AUTOSAR XML (schema 4-2-2)
standard types defined: boolean, uint8
package /Communication/DataTransformation
  data transformation set New_Transformer_Configuration
    transformation technology Fingerprint_SOME_IP_Transformer: someip-transformation-description=byte-order=big-endian
package /Communication/PDUs
  pdu Delete_RequestSignalIPDU: contained-i-pdu-props={collection-semantics=LAST-IS-BEST, header-id-short-header=1}
    signal Delete_Request: 4 bit, compu-method=DeleteFunction_FingerPrintDelete1, someip-transformation-i-signal-props=Fingerprint_SOME_IP_Transformer, to TC297
  pdu Delete_ResultSignalIPDU: contained-i-pdu-props={collection-semantics=LAST-IS-BEST, header-id-short-header=2}
    signal Delete_Result: 1 bit, compu {0=Delete_Result_Sucessful, 1=Delete_Result_Failed}, someip-transformation-i-signal-props=Fingerprint_SOME_IP_Transformer, to J6
  pdu DoorStatusSignalIPDU: contained-i-pdu-props={collection-semantics=LAST-IS-BEST, header-id-short-header=3}
    signal DoorStatus: 1 bit, big-endian, compu {0=DoorStatusClosed, 1=DoorStatusOpen}, someip-transformation-i-signal-props=Fingerprint_SOME_IP_Transformer, to J6
  4 x i signal i pdu group:
    J6_BusSystem57_Rx: communication-direction=IN
      i-signal-i-pdus:
        Learn_PercentSignalIPDU
        Inactive_ResultSignalIPDU
        PowermodeSignalIPDU
        Delete_ResultSignalIPDU
        DoorStatusSignalIPDU
        Learn_ResultSignalIPDU
    J6_BusSystem57_Tx: communication-direction=OUT, i-signal-i-pdus=[Inactive_RequestSignalIPDU, Delete_RequestSignalIPDU, Learn_RequestSignalIPDU]
    TC297_BusSystem56_Rx: communication-direction=IN, i-signal-i-pdus=[Learn_RequestSignalIPDU, Delete_RequestSignalIPDU, Inactive_RequestSignalIPDU]
    TC297_BusSystem56_Tx: communication-direction=OUT
      i-signal-i-pdus:
        PowermodeSignalIPDU
        DoorStatusSignalIPDU
        Inactive_ResultSignalIPDU
        Delete_ResultSignalIPDU
        Learn_ResultSignalIPDU
        Learn_PercentSignalIPDU
  pdu Inactive_RequestSignalIPDU
    signal Inactive_Request: 1 bit, compu {0=Learn_Inactive}, someip-transformation-i-signal-props=Fingerprint_SOME_IP_Transformer, to TC297
  pdu Inactive_ResultSignalIPDU: contained-i-pdu-props={collection-semantics=LAST-IS-BEST, header-id-short-header=4}
    signal Inactive_Result: 1 bit, compu {0=Inactive_ResultSucessful, 1=Inactive_ResultFailed}, someip-transformation-i-signal-props=Fingerprint_SOME_IP_Transformer, to J6
  pdu Learn_PercentSignalIPDU: contained-i-pdu-props={collection-semantics=LAST-IS-BEST, header-id-short-header=6}
    signal Learn_Percent: 8 bit, someip-transformation-i-signal-props=Fingerprint_SOME_IP_Transformer, to J6
  pdu Learn_RequestSignalIPDU: contained-i-pdu-props={collection-semantics=LAST-IS-BEST, header-id-short-header=7}
    signal Learn_Request: 1 bit, compu {0=Learn_Active}, someip-transformation-i-signal-props=Fingerprint_SOME_IP_Transformer, to TC297
  pdu Learn_ResultSignalIPDU: contained-i-pdu-props={collection-semantics=LAST-IS-BEST, header-id-short-header=8}
    signal Learn_Result: 3 bit, compu-method=Learn_Result1, someip-transformation-i-signal-props=Fingerprint_SOME_IP_Transformer, to J6
  pdu PowermodeSignalIPDU: contained-i-pdu-props={collection-semantics=LAST-IS-BEST, header-id-short-header=9}
    signal Powermode: 2 bit, compu {1=SwitchRequest_ACC, 0=SwitchRequest_OFF, 2=SwitchRequest_RUN}, someip-transformation-i-signal-props=Fingerprint_SOME_IP_Transformer, to J6
package /DataTypeMappingSets
  data type mapping set Data_Type_Mappings
    data-type-maps:
      application-data-type=AdtDelete_Request1, implementation-data-type=IdtDelete_Request1
      application-data-type=AdtDelete_Status1, implementation-data-type=IdtDelete_Status1
      application-data-type=AdtDoorStatus1, implementation-data-type=IdtDoorStatus1
      application-data-type=AdtLearn_Inative1, implementation-data-type=IdtLearn_Inative1
      application-data-type=AdtLearn_Percent1, implementation-data-type=IdtLearn_Percent1
      application-data-type=AdtInactive_Result1, implementation-data-type=IdtInactive_Result1
      application-data-type=AdtLearn_Request1, implementation-data-type=IdtLearn_Request1
      application-data-type=AdtLearn_Result1, implementation-data-type=IdtLearn_Result1
      application-data-type=AdtPowerModeStatus1, implementation-data-type=IdtPowerModeStatus1
package /DataTypes/ApplicationDataTypes
  9 x app type:
    AdtDelete_Request1: category=VALUE, compu-method=DeleteFunction_FingerPrintDelete1
    AdtDelete_Status1: category=BOOLEAN, sw-calibration-access=READ-WRITE, compu {0=Delete_Result_Sucessful, 1=Delete_Result_Failed}, sw-interpolation-method=USEINPUTNEAREST
    AdtDoorStatus1: category=BOOLEAN, sw-calibration-access=READ-WRITE, compu {0=DoorStatusClosed, 1=DoorStatusOpen}, sw-refresh-timing={cse-code=3, cse-code-factor=200}
    AdtInactive_Result1: category=BOOLEAN, compu {0=Inactive_ResultSucessful, 1=Inactive_ResultFailed}
    AdtLearn_Inative1: category=BOOLEAN, compu {0=Learn_Inactive}
    AdtLearn_Percent1: category=VALUE, sw-calibration-access=READ-WRITE, sw-interpolation-method=USEINPUTNEAREST
    AdtLearn_Request1: category=BOOLEAN, compu {0=Learn_Active}
    AdtLearn_Result1: category=VALUE, compu-method=Learn_Result1, sw-interpolation-method=USEINPUTNEAREST
    AdtPowerModeStatus1: category=VALUE, compu {1=SwitchRequest_ACC, 0=SwitchRequest_OFF, 2=SwitchRequest_RUN}
package /DataTypes/BaseTypes
  base type boolean_1: category=FIXED_LENGTH, base-type-size=8, max-base-type-size=0, base-type-encoding=BOOLEAN, mem-alignment=0, byte-order=big-endian, native-declaration=boolean
  base type uint8_1: category=FIXED_LENGTH, base-type-size=8, max-base-type-size=0, base-type-encoding=NONE, mem-alignment=0, byte-order=big-endian, native-declaration=uint8
package /DataTypes/CompuMethods
  compu method DeleteFunction_FingerPrintDelete1: 0=Delete_AllFingers, 1=Delete_Finger1, 2=Delete_Finger2, 3=Delete_Finger3, 8=Delete_Finger8, 4..7=Delete_Finger4..Delete_Finger7
  compu method DeleteFunction_ITS_FingerPrintDelete: 0=Delete_AllFingers, 1=Delete_Finger1, 2=Delete_Finger2, 3=Delete_Finger3, 8=Delete_Finger8, 4..7=Delete_Finger4..Delete_Finger7
  compu method Learn_Result1: 0=Learn_ActiveResult_Sucessful, 1=Learn_ActiveResult_failed, 2=Learn_ActiveResult_ITScheckfailed, 3=Learn_ActiveResult_ETScheckfailed, 4=Learning_ActiveResult_ITScheckSucessful
package /DataTypes/ImplementationDataTypes
  10 x impl type, all with category=VALUE:
    IdtDelete_Request: base-type=uint8, sw-calibration-access=READ-WRITE, compu-method=DeleteFunction_ITS_FingerPrintDelete, invalid-value=X1:-1
    IdtDelete_Request1: base-type=uint8, sw-calibration-access=READ-WRITE, compu-method=DeleteFunction_ITS_FingerPrintDelete, invalid-value=X1:-1
    IdtDelete_Status1: base-type=boolean, sw-calibration-access=READ-WRITE, compu {0=Delete_Result_Sucessful, 1=Delete_Result_Failed}, invalid-value=X1:-1
    IdtDoorStatus1: base-type=boolean, sw-calibration-access=READ-WRITE, compu {0=DoorStatusClosed, 1=DoorStatusOpen}, invalid-value=X1:-1, sw-refresh-timing={cse-code=3, cse-code-factor=200}
    IdtInactive_Result1: compu {0=Inactive_ResultSucessful, 1=Inactive_ResultFailed}
    IdtLearn_Inative1: base-type=boolean, sw-calibration-access=READ-WRITE, compu {0=Learn_Inactive}, invalid-value=X1:-1
    IdtLearn_Percent1: base-type=uint8, sw-calibration-access=READ-WRITE, invalid-value=X1:-1
    IdtLearn_Request1: base-type=boolean, sw-calibration-access=READ-WRITE, compu {0=Learn_Active}, invalid-value=X1:-1
    IdtLearn_Result1: base-type=uint8, sw-calibration-access=READ-WRITE, compu {0=Learn_ActiveResult_Sucessful, 1=Learn_ActiveResult_failed, 2=Learn_ActiveResult_ITScheckfailed, 3=Learn_ActiveResult_ETScheckfailed, 4=Learning_ActiveResult_ITScheckSucessful}, invalid-value=X1:-1
    IdtPowerModeStatus1: base-type=uint8, sw-calibration-access=READ-WRITE, compu {1=SwitchRequest_ACC, 0=SwitchRequest_OFF, 2=SwitchRequest_RUN}, invalid-value=X1:-1, sw-refresh-timing={cse-code=3, cse-code-factor=200}
package /SoftwareTypes/ComponentTypes
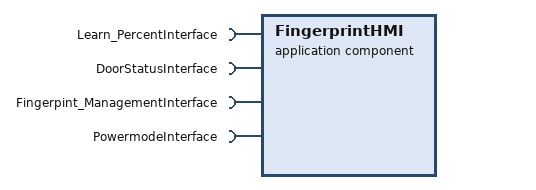
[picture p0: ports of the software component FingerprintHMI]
  application sw component type FingerprintHMI
    4 x require port:
      Learn_PercentInterface: required-interface=Learn_PercentInterface
      DoorStatusInterface: required-interface=DoorStatusInterface
      Fingerpint_ManagementInterface: required-interface=Fingerpint_ManagementInterface
      PowermodeInterface: required-interface=PowermodeInterface
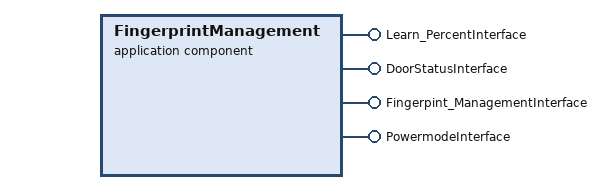
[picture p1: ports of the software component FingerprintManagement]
  application sw component type FingerprintManagement
    4 x provide port:
      Learn_PercentInterface: provided-interface=Learn_PercentInterface
      DoorStatusInterface: provided-interface=DoorStatusInterface
      Fingerpint_ManagementInterface: provided-interface=Fingerpint_ManagementInterface
      PowermodeInterface: provided-interface=PowermodeInterface
  composition sw component type CtCotc297_J6
    component FingerprintHMI_J6: type=FingerprintHMI
    component FingerprintManagement_TC297: type=FingerprintManagement
    connect FingerprintManagement_TC297.Learn_PercentInterface -> FingerprintHMI_J6.Learn_PercentInterface
    connect FingerprintManagement_TC297.DoorStatusInterface -> FingerprintHMI_J6.DoorStatusInterface
    connect FingerprintManagement_TC297.Fingerpint_ManagementInterface -> FingerprintHMI_J6.Fingerpint_ManagementInterface
    connect FingerprintManagement_TC297.PowermodeInterface -> FingerprintHMI_J6.PowermodeInterface
  composition sw component type Fingerprint
    component CtCotc297_J6: type=CtCotc297_J6
package /SoftwareTypes/Interfaces
  client server interface Fingerpint_ManagementInterface
    operation HMI_FingerPrint_Active
      arg Learn_Active: type=AdtLearn_Request1, direction=IN
      arg Learn_Result: type=AdtLearn_Result1, direction=OUT
    operation HMI_FingerPrint_Delete
      arg Delete_Request: type=AdtDelete_Request1, direction=IN
      arg Delete_Result: type=AdtDelete_Status1, direction=OUT
    operation HMI_FingerPrint_Inactive
      arg Inactive_Request: type=AdtLearn_Inative1, direction=IN
      arg Inactive_Result: type=AdtInactive_Result1, direction=OUT
  sender receiver interface DoorStatusInterface
    data DoorStatusDataElement: type=AdtDoorStatus1
  sender receiver interface Learn_PercentInterface
    data Learn_PercentDataElement: type=AdtLearn_Percent1
  sender receiver interface PowermodeInterface
    data PowermodeDataElement: type=AdtPowerModeStatus1
package /System
  system System: category=SYSTEM_DESCRIPTION
    system mapping Mapping
      data-mappings:
        client-server-to-signal-mapping={call-signal=Delete_Request, client-server-operation=Fingerprint.CtCotc297_J6.FingerprintManagement_TC297.Fingerpint_ManagementInterface.HMI_FingerPrint_Delete}
        client-server-to-signal-mapping={client-server-operation=Fingerprint.CtCotc297_J6.FingerprintHMI_J6.Fingerpint_ManagementInterface.HMI_FingerPrint_Inactive, return-signal=Inactive_Result}
        client-server-to-signal-mapping={client-server-operation=Fingerprint.CtCotc297_J6.FingerprintHMI_J6.Fingerpint_ManagementInterface.HMI_FingerPrint_Active, return-signal=Learn_Result}
        client-server-to-signal-mapping={client-server-operation=Fingerprint.CtCotc297_J6.FingerprintHMI_J6.Fingerpint_ManagementInterface.HMI_FingerPrint_Delete, return-signal=Delete_Result}
        client-server-to-signal-mapping={call-signal=Inactive_Request, client-server-operation=Fingerprint.CtCotc297_J6.FingerprintManagement_TC297.Fingerpint_ManagementInterface.HMI_FingerPrint_Inactive}
        client-server-to-signal-mapping={call-signal=Learn_Request, client-server-operation=Fingerprint.CtCotc297_J6.FingerprintManagement_TC297.Fingerpint_ManagementInterface.HMI_FingerPrint_Active}
        sender-receiver-to-signal-mapping={data-element=CtCotc297_J6.FingerprintHMI_J6.Fingerprint.DoorStatusInterface.DoorStatusDataElement, system-signal=DoorStatus}
        sender-receiver-to-signal-mapping={data-element=CtCotc297_J6.FingerprintManagement_TC297.Fingerprint.DoorStatusInterface.DoorStatusDataElement, system-signal=DoorStatus}
        sender-receiver-to-signal-mapping={data-element=CtCotc297_J6.FingerprintManagement_TC297.Fingerprint.Learn_PercentInterface.Learn_PercentDataElement, system-signal=Learn_Percent}
        sender-receiver-to-signal-mapping={data-element=CtCotc297_J6.FingerprintHMI_J6.Fingerprint.Learn_PercentInterface.Learn_PercentDataElement, system-signal=Learn_Percent}
        sender-receiver-to-signal-mapping={data-element=CtCotc297_J6.FingerprintHMI_J6.Fingerprint.PowermodeInterface.PowermodeDataElement, system-signal=Powermode}
        sender-receiver-to-signal-mapping={data-element=CtCotc297_J6.FingerprintManagement_TC297.Fingerprint.PowermodeInterface.PowermodeDataElement, system-signal=Powermode}
      sw-mappings:
        swc to ecu mapping SW_NET_Component_Mapping237: component=Fingerprint.CtCotc297_J6.FingerprintManagement_TC297, ecu-instance=TC297
        swc to ecu mapping SW_NET_Component_Mapping236: component=Fingerprint.CtCotc297_J6.FingerprintHMI_J6, ecu-instance=J6
    root-software-compositions:
      root sw composition prototype Fingerprint: software-composition=Fingerprint
package /Topology/Clusters
  ethernet cluster FingerprintEthernetCluster
    ethernet physical channel ChannelCommunication195: comm-connectors=[BA_J6_0_EEI, BA_TC297_0_EEI]
      pdu triggering DoorStatusPDUTransmission: pdu=DoorStatusSignalIPDU, from TC297, to J6
      pdu triggering Learn_PercentPDUTransmission: pdu=Learn_PercentSignalIPDU, from TC297, to J6
      pdu triggering Inactive_ResultPDUTransmission: pdu=Inactive_ResultSignalIPDU, from TC297, to J6
      pdu triggering Learn_ResultPDUTransmission: pdu=Learn_ResultSignalIPDU, from TC297, to J6
      pdu triggering Delete_ResultPDUTransmission: pdu=Delete_ResultSignalIPDU, from TC297, to J6
      pdu triggering PowermodePDUTransmission: pdu=PowermodeSignalIPDU, from TC297, to J6
      pdu triggering Learn_RequestPDUTransmission: pdu=Learn_RequestSignalIPDU, from J6, to TC297
      pdu triggering Inactive_RequestPDUTransmission: pdu=Inactive_RequestSignalIPDU, from J6, to TC297
      pdu triggering Delete_RequestPDUTransmission: pdu=Delete_RequestSignalIPDU, from J6, to TC297
      network endpoint BA_TC297_NEP: network-endpoint-addresses=ipv-4-configuration=ipv-4-address=192.168.1.10
      network endpoint BA_J6_NEP: network-endpoint-addresses=ipv-4-configuration={ipv-4-address=192.168.1.20, ipv-4-address-source=AUTO-IP}
      so-ad-config:
        socket connection bundle TC297_J6FinggerprintSocketConnectionBundle: socket-connection{client-port=J6SocketAddress, pdus=[{header-id=65535, pdu-triggering=Inactive_ResultPDUTransmission}, {header-id=65534, pdu-triggering=Learn_ResultPDUTransmission}, {header-id=65533, pdu-triggering=Delete_ResultPDUTransmission}, {header-id=65532, pdu-triggering=Learn_RequestPDUTransmission}, {header-id=65531, pdu-triggering=Inactive_RequestPDUTransmission}, {header-id=65530, pdu-triggering=Delete_RequestPDUTransmission}, {header-id=65529, pdu-triggering=DoorStatusPDUTransmission}, {header-id=65528, pdu-triggering=Learn_PercentPDUTransmission}, {header-id=65527, pdu-triggering=PowermodePDUTransmission}]}, server-port=TC297SocketAddress
        socket address J6SocketAddress: connector=BA_J6_0_EEI
          application endpoint BA_J6_0_EEI: network-endpoint=BA_J6_NEP, tp-configuration=tcp-tp=tcp-tp-port=port-number=100
            consumed service instance newCSI
        socket address TC297SocketAddress: connector=BA_TC297_0_EEI
          application endpoint BA_TC297_0_EEI: network-endpoint=BA_TC297_NEP, tp-configuration=tcp-tp=tcp-tp-port=port-number=100
            provided service instance newPSI
      vlan Fingerprint_Vlan: vlan-identifier=10
    coupling-port-connections:
      first-port=BA_TC297_0, second-port=BA_Switch_TC297_J6_0
      first-port=BA_J6_0, second-port=BA_Switch_TC297_J6_1
package /Topology/HardwareComponents
  coupling element CouplingElement8: communication-cluster=FingerprintEthernetCluster, coupling-type=SWITCH
    coupling port BA_Switch_TC297_J6_0: default-vlan=ChannelCommunication195, vlan-membership{send-activity=SENT-TAGGED, vlan=ChannelCommunication195}
    coupling port BA_Switch_TC297_J6_1: default-vlan=ChannelCommunication195, vlan-membership{send-activity=SENT-TAGGED, vlan=ChannelCommunication195}
  ecu instance J6: associated-com-i-pdu-group=[J6_BusSystem57_Tx, J6_BusSystem57_Rx], sleep-mode-supported=false, wake-up-over-bus-supported=false
    ethernet communication controller BA_J6_0_EPC: mac-unicast-address=AA:BB:CC:DD:00:02
      coupling port BA_J6_0: connection-negotiation-behavior=AUTO, physical-layer-type=BROAD-R-REACH, vlan-membership{default-priority=1, vlan=ChannelCommunication195}
    ethernet communication connector BA_J6_0_EEI: comm-controller=BA_J6_0_EPC, network-endpoint=BA_J6_NEP
  ecu instance TC297: associated-com-i-pdu-group=[TC297_BusSystem56_Tx, TC297_BusSystem56_Rx], sleep-mode-supported=false, wake-up-over-bus-supported=false
    ethernet communication controller BA_TC297_0_EPC: mac-unicast-address=AA:BB:CC:DD:00:01
      coupling port BA_TC297_0: connection-negotiation-behavior=AUTO, physical-layer-type=BROAD-R-REACH, vlan-membership{default-priority=1, vlan=ChannelCommunication195}
    ethernet communication connector BA_TC297_0_EEI: comm-controller=BA_TC297_0_EPC, network-endpoint=BA_TC297_NEP
